# ATmega1284RFR2 register map
Vendor: Atmel; File version: 1.0
CPU: other r0p0, little endian, no MPU, no FPU, 4 interrupt priority bits
Registers are 8-bit, read-write, reset 0x0 unless marked. A register's access mark holds for its fields unless they carry their own. Offsets are from the block's base; [hi:lo] are bit positions; 'fields as' and 'values as' point back to an identical list.

## TC2 — Timer/Counter, 8-bit Async
Base 0x00800037
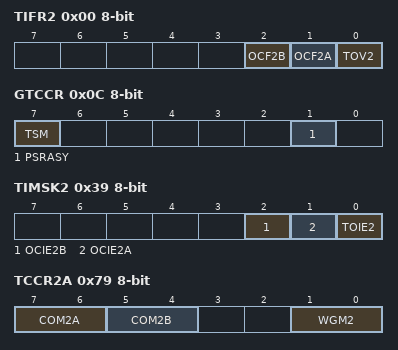
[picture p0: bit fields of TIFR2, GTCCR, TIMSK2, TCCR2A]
0x00 TIFR2 — Timer/Counter Interrupt Flag Register (read-only for debugger)
  [2] OCF2B — Output Compare Flag 2 B
  [1] OCF2A — Output Compare Flag 2 A
  [0] TOV2 — Timer/Counter2 Overflow Flag
0x0C GTCCR — General Timer Counter Control register
  [7] TSM — Timer/Counter Synchronization Mode
  [1] PSRASY — Prescaler Reset Timer/Counter2
0x39 TIMSK2 — Timer/Counter Interrupt Mask register
  [2] OCIE2B — Timer/Counter2 Output Compare Match B Interrupt Enable
  [1] OCIE2A — Timer/Counter2 Output Compare Match A Interrupt Enable
  [0] TOIE2 — Timer/Counter2 Overflow Interrupt Enable
0x79 TCCR2A — Timer/Counter2 Control Register A
  [7:6] COM2A — Compare Match Output A Mode
    0=NORMAL_PORT_OPERATION_OC2A_DISCONNECTED; 1=TOGGLE_OC2A_ON_COMPARE_MATCH; 2=CLEAR_OC2A_ON_COMPARE_MATCH; 3=SET_OC2A_ON_COMPARE_MATCH
  [5:4] COM2B — Compare Match Output B Mode
    0=NORMAL_PORT_OPERATION_OC2B_DISCONNECTED; 1=TOGGLE_OC2B_ON_COMPARE_MATCH; 2=CLEAR_OC2B_ON_COMPARE_MATCH; 3=SET_OC2B_ON_COMPARE_MATCH
  [1:0] WGM2 — Waveform Generation Mode
    0=NORMAL_MODE_OF_OPERATION; 1=PWM_PHASE_CORRECT_TOP_0XFF; 2=CTC_TOP_OCRA; 3=FAST_PWM_TOP_0XFF
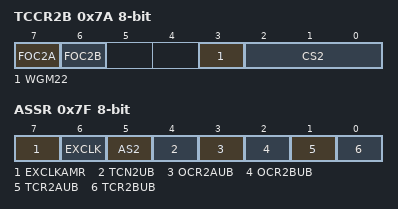
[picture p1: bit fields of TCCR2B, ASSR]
0x7A TCCR2B — Timer/Counter2 Control Register B
  [7] FOC2A — Force Output Compare A
  [6] FOC2B — Force Output Compare B
  [3] WGM22 — Waveform Generation Mode
  [2:0] CS2 — Clock Select
    0=NO_CLOCK_SOURCE_TIMER_COUNTER2_STOPPED; 1=CLK_T2S_1_NO_PRESCALING; 2=CLK_T2S_8_FROM_PRESCALER; 3=CLK_T2S_32_FROM_PRESCALER; 4=CLK_T2S_64_FROM_PRESCALER; 5=CLK_T2S_128_FROM_PRESCALER; 6=CLK_T2S_256_FROM_PRESCALER; 7=CLK_T2S_1024_FROM_PRESCALER
0x7B TCNT2 — Timer/Counter2
0x7C OCR2A — Timer/Counter2 Output Compare Register A
0x7D OCR2B — Timer/Counter2 Output Compare Register B
0x7F ASSR — Asynchronous Status Register
  [7] EXCLKAMR — Enable External Clock Input for AMR
  [6] EXCLK — Enable External Clock Input
  [5] AS2 — Timer/Counter2 Asynchronous Mode
  [4] TCN2UB — Timer/Counter2 Update Busy
  [3] OCR2AUB — Timer/Counter2 Output Compare Register A Update Busy
  [2] OCR2BUB — Timer/Counter2 Output Compare Register B Update Busy
  [1] TCR2AUB — Timer/Counter2 Control Register A Update Busy
  [0] TCR2BUB — Timer/Counter2 Control Register B Update Busy

## TC3 — Timer/Counter, 16-bit
Base 0x00800038
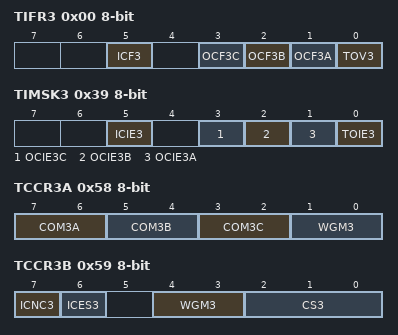
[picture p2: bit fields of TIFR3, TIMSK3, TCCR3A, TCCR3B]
0x00 TIFR3 — Timer/Counter3 Interrupt Flag Register (read-only for debugger)
  [5] ICF3 — Timer/Counter3 Input Capture Flag
  [3] OCF3C — Timer/Counter3 Output Compare C Match Flag
  [2] OCF3B — Timer/Counter3 Output Compare B Match Flag
  [1] OCF3A — Timer/Counter3 Output Compare A Match Flag
  [0] TOV3 — Timer/Counter3 Overflow Flag
0x39 TIMSK3 — Timer/Counter3 Interrupt Mask Register
  [5] ICIE3 — Timer/Counter3 Input Capture Interrupt Enable
  [3] OCIE3C — Timer/Counter3 Output Compare C Match Interrupt Enable
  [2] OCIE3B — Timer/Counter3 Output Compare B Match Interrupt Enable
  [1] OCIE3A — Timer/Counter3 Output Compare A Match Interrupt Enable
  [0] TOIE3 — Timer/Counter3 Overflow Interrupt Enable
0x58 TCCR3A — Timer/Counter3 Control Register A
  [7:6] COM3A — Compare Output Mode for Channel A
    0=NORMAL_PORT_OPERATION_OCNA_OCNB_OCNC_DISCONNECTED; 1=TOGGLE_OCNA_OCNB_OCNC_ON_COMPARE_MATCH; 2=CLEAR_OCNA_OCNB_OCNC_ON_COMPARE_MATCH_SET_OUTPUT_TO_LOW_LEVEL; 3=SET_OCNA_OCNB_OCNC_ON_COMPARE_MATCH_SET_OUTPUT_TO_HIGH_LEVEL
  [5:4] COM3B — Compare Output Mode for Channel B
    values as COM3A
  [3:2] COM3C — Compare Output Mode for Channel C
    values as COM3A
  [1:0] WGM3 — Waveform Generation Mode
    0=NORMAL_MODE_OF_OPERATION; 1=PWM_PHASE_CORRECT_8_BIT; 2=PWM_PHASE_CORRECT_9_BIT; 3=PWM_PHASE_CORRECT_10_BIT
0x59 TCCR3B — Timer/Counter3 Control Register B
  [7] ICNC3 — Input Capture 3 Noise Canceller
  [6] ICES3 — Input Capture 3 Edge Select
  [4:3] WGM3 — Waveform Generation Mode
    values as TCCR3A.WGM3
  [2:0] CS3 — Clock Select
    0=NO_CLOCK_SOURCE_TIMER_COUNTER_STOPPED; 1=CLK_IO_1_NO_PRESCALING; 2=CLK_IO_8_FROM_PRESCALER; 3=CLK_IO_64_FROM_PRESCALER; 4=CLK_IO_256_FROM_PRESCALER; 5=CLK_IO_1024_FROM_PRESCALER; 6=EXTERNAL_CLOCK_SOURCE_ON_TN_PIN_CLOCK_ON_FALLING_EDGE; 7=EXTERNAL_CLOCK_SOURCE_ON_TN_PIN_CLOCK_ON_RISING_EDGE
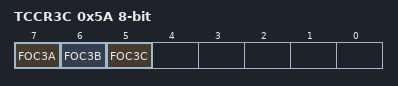
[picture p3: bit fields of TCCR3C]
0x5A TCCR3C — Timer/Counter3 Control Register C
  [7] FOC3A — Force Output Compare for Channel A
  [6] FOC3B — Force Output Compare for Channel B
  [5] FOC3C — Force Output Compare for Channel C
0x5C TCNT3 16-bit (reset mask 0xFF) — Timer/Counter3 Bytes
0x5E ICR3 16-bit (reset mask 0xFF) — Timer/Counter3 Input Capture Register Bytes
0x60 OCR3A 16-bit (reset mask 0xFF) — Timer/Counter3 Output Compare Register A Bytes
0x62 OCR3B 16-bit (reset mask 0xFF) — Timer/Counter3 Output Compare Register B Bytes
0x64 OCR3C 16-bit (reset mask 0xFF) — Timer/Counter3 Output Compare Register C Bytes
